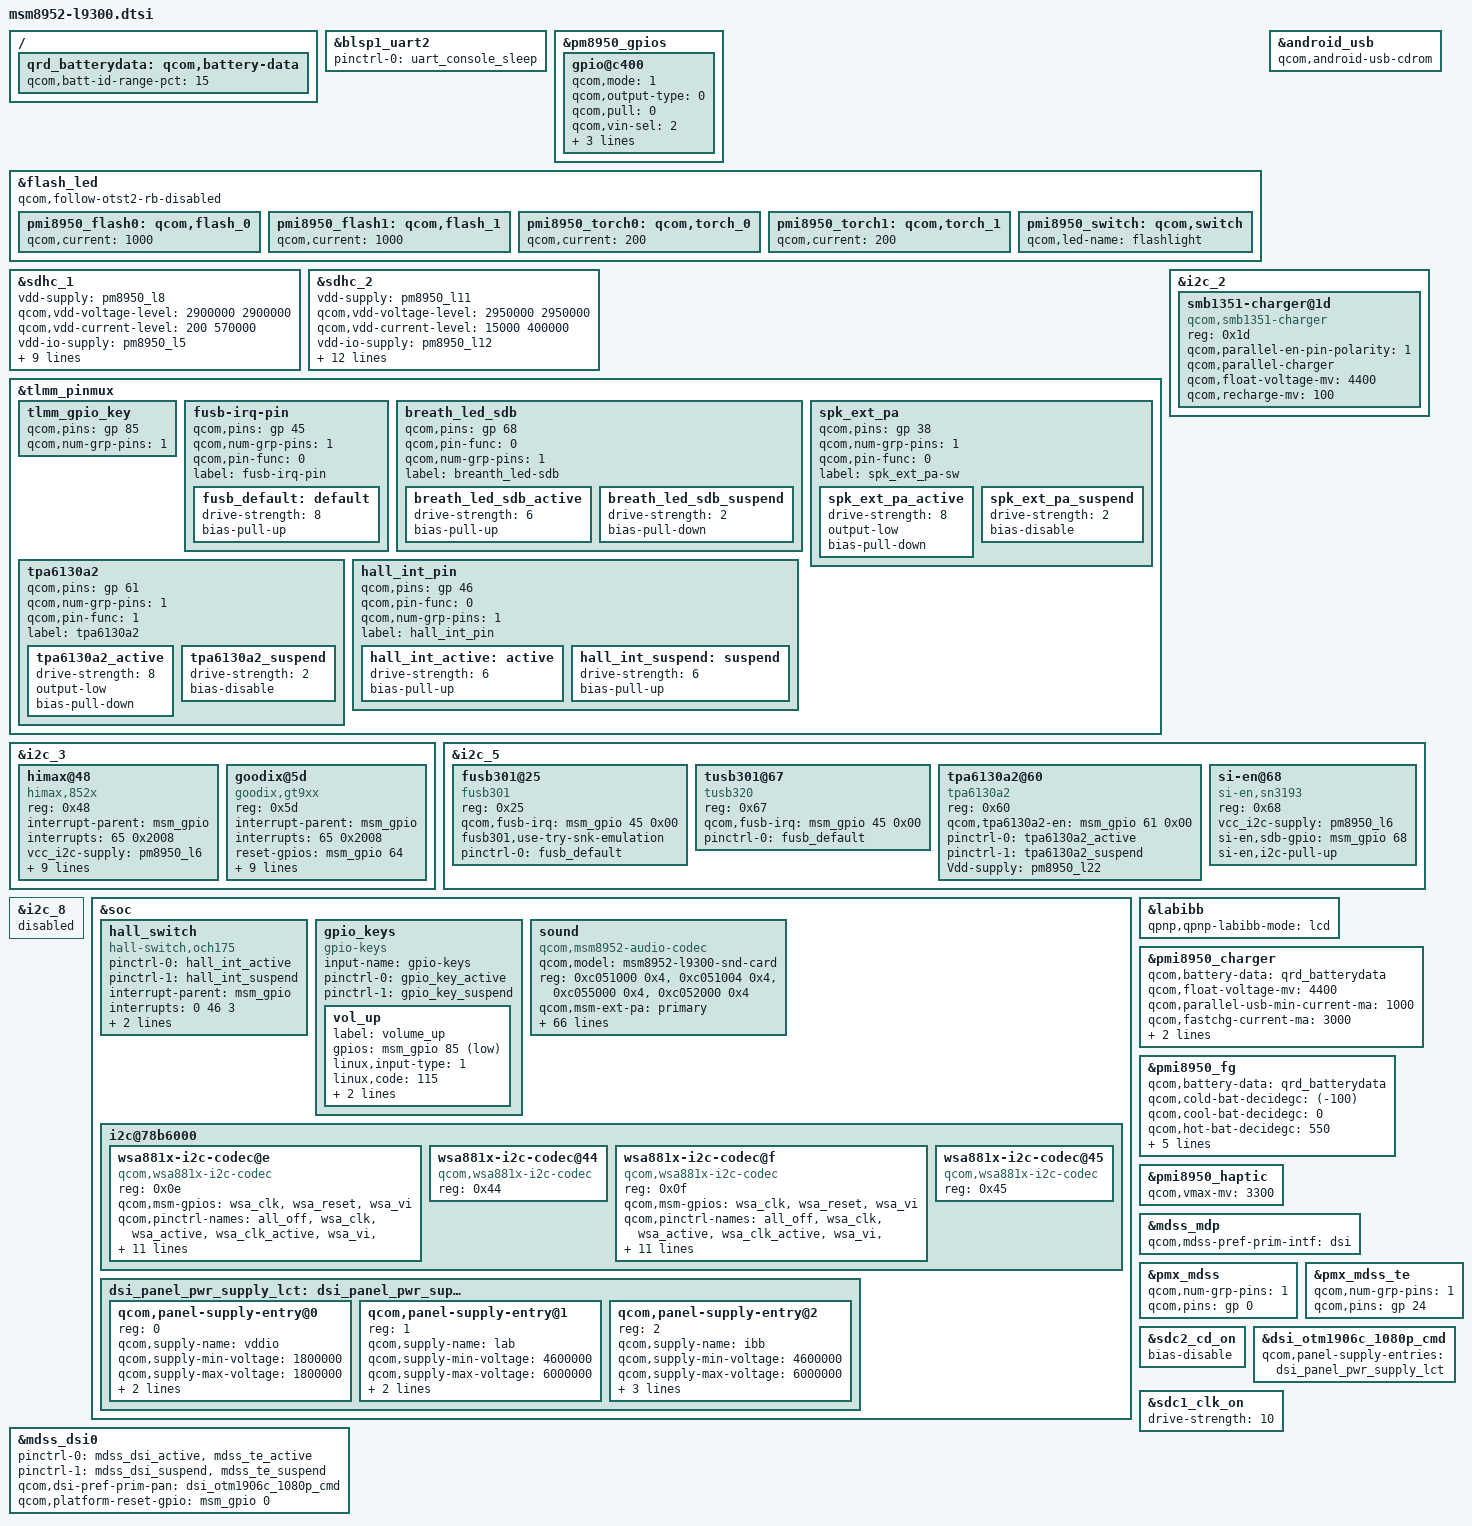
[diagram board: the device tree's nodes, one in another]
/*
 * Copyright (c) 2015, The Linux Foundation. All rights reserved.
 *
 * This program is free software; you can redistribute it and/or modify
 * it under the terms of the GNU General Public License version 2 and
 * only version 2 as published by the Free Software Foundation.
 *
 * This program is distributed in the hope that it will be useful,
 * but WITHOUT ANY WARRANTY; without even the implied warranty of
 * MERCHANTABILITY or FITNESS FOR A PARTICULAR PURPOSE.  See the
 * GNU General Public License for more details.
 */

#include "msm8952.dtsi"
#include "msm8952-camera-sensor-l9300.dtsi"
#include "dsi-panel-truly-hx8399c-1080p-video.dtsi"
#include "dsi-panel-dijing-otm1901a-1080p-video.dtsi"
#include "dsi-panel-truly-r63350-1080p-video.dtsi"

&blsp1_uart2 {
        status = "ok";
        pinctrl-names = "default";
        pinctrl-0 = <&uart_console_sleep>;
};

&pm8950_gpios {
        gpio@c400 {
                qcom,mode = <1>;
                qcom,output-type = <0>;
                qcom,pull = <0>;
                qcom,vin-sel = <2>;
                qcom,out-strength = <3>;
                qcom,src-sel = <0>;
                qcom,master-en = <1>;
                status = "okay";
        };
};

&flash_led {
        qcom,follow-otst2-rb-disabled;

        pmi8950_flash0: qcom,flash_0 {
                qcom,current = <1000>;
        };
        pmi8950_flash1: qcom,flash_1 {
                qcom,current = <1000>;
        };
        pmi8950_torch0: qcom,torch_0 {
                qcom,current = <200>;
        };
        pmi8950_torch1: qcom,torch_1 {
                qcom,current = <200>;
        };
        pmi8950_switch: qcom,switch {
                qcom,led-name = "flashlight";
        };
};

&sdhc_1 {
        vdd-supply = <&pm8950_l8>;
        qcom,vdd-voltage-level = <2900000 2900000>;
        qcom,vdd-current-level = <200 570000>;

        vdd-io-supply = <&pm8950_l5>;
        qcom,vdd-io-always-on;
        qcom,vdd-io-lpm-sup;
        qcom,vdd-io-voltage-level = <1800000 1800000>;
        qcom,vdd-io-current-level = <200 325000>;

        pinctrl-names = "active", "sleep";
        pinctrl-0 = <&sdc1_clk_on &sdc1_cmd_on &sdc1_data_on &sdc1_rclk_on>;
        pinctrl-1 = <&sdc1_clk_off &sdc1_cmd_off &sdc1_data_off &sdc1_rclk_off>;

        qcom,nonremovable;

        status = "ok";
};

&sdhc_2 {
        vdd-supply = <&pm8950_l11>;
        qcom,vdd-voltage-level = <2950000 2950000>;
        qcom,vdd-current-level = <15000 400000>;

        vdd-io-supply = <&pm8950_l12>;
        qcom,vdd-io-voltage-level = <1800000 2950000>;
        qcom,vdd-io-current-level = <200 22000>;

        pinctrl-names = "active", "sleep";
        pinctrl-0 = <&sdc2_clk_on &sdc2_cmd_on &sdc2_data_on &sdc2_cd_on>;
        pinctrl-1 = <&sdc2_clk_off &sdc2_cmd_off &sdc2_data_off &sdc2_cd_off>;

        #address-cells = <0>;
        interrupt-parent = <&sdhc_2>;
        interrupts = <0 1 2>;
        #interrupt-cells = <1>;
        interrupt-map-mask = <0xffffffff>;
        interrupt-map = <0 &intc 0 125 0
                        1 &intc 0 221 0
                        2 &msm_gpio 67 0>;
        interrupt-names = "hc_irq", "pwr_irq", "status_irq";
        cd-gpios = <&msm_gpio 67 0x0>;

        status = "ok";
};

&android_usb {
        qcom,android-usb-cdrom;
};

&tlmm_pinmux {
	tlmm_gpio_key {
		qcom,pins = <&gp 85>;
		qcom,num-grp-pins = <1>;
	};

	fusb-irq-pin {
		qcom,pins = <&gp 45>;
		qcom,num-grp-pins = <1>;
		qcom,pin-func = <0>;
		label = "fusb-irq-pin";
		fusb_default: default {
			drive-strength = <8>;
			bias-pull-up;
		};
	};

	breath_led_sdb {
		/* sn3193 breath led */
		qcom,pins = <&gp 68>;
		qcom,pin-func = <0>;
		qcom,num-grp-pins = <1>;
		label = "breanth_led-sdb";
		breath_led_sdb_active: breath_led_sdb_active {
			drive-strength = <6>;
			bias-pull-up;
		};
		breath_led_sdb_suspend: breath_led_sdb_suspend {
			drive-strength = <2>;
			bias-pull-down;
		};
	};

	spk_ext_pa {
		qcom,pins = <&gp 38>;
		qcom,num-grp-pins = <1>;
		qcom,pin-func = <0>;
		label = "spk_ext_pa-sw";
		spk_ext_pa_active: spk_ext_pa_active {
			drive-strength = <8>;
			output-low;
			bias-pull-down;
		};
		spk_ext_pa_suspend: spk_ext_pa_suspend {
			drive-strength = <2>;
			bias-disable;
		};
	};

	tpa6130a2 {
		qcom,pins = <&gp 61>;
		qcom,num-grp-pins = <1>;
		qcom,pin-func = <1>;
		label = "tpa6130a2";
		tpa6130a2_active: tpa6130a2_active {
			drive-strength = <8>;
			output-low;
			bias-pull-down;
		};
		tpa6130a2_suspend: tpa6130a2_suspend {
			drive-strength = <2>;
			bias-disable;
		};
	};

	hall_int_pin {
		qcom,pins = <&gp 46>;
		qcom,pin-func = <0>;
		qcom,num-grp-pins = <1>;
		label = "hall_int_pin";
		hall_int_active: active {
			drive-strength = <6>;
			bias-pull-up;
		};
		hall_int_suspend: suspend {
			drive-strength = <6>;
			bias-pull-up;
		};
	};
};

&i2c_2 {
	/* Parallel-charger configuration */
	smb1351-charger@1d {
		compatible = "qcom,smb1351-charger";
		reg = <0x1d>;
		qcom,parallel-en-pin-polarity = <1>;
		qcom,parallel-charger;
		qcom,float-voltage-mv = <4400>;
		qcom,recharge-mv = <100>;
	};
};

&i2c_3 { /* BLSP1 QUP3 */
	himax@48{
		compatible = "himax,852x";
		reg = <0x48>;
		interrupt-parent = <&msm_gpio>;
		interrupts = <65 0x2008>;
		vcc_i2c-supply = <&pm8950_l6>;
		himax,family-id = <0x82>;
		himax,reset-gpio = <&msm_gpio 64 0x0>;
		himax,power_ldo-gpio = <&msm_gpio 91 0x0>;
		himax,irq-gpio = <&msm_gpio 65 0x2008>;
		himax,display-coords = <0 1080 0 1920>;
		himax,panel-coords = <0 1080 0 1920>;
		himax,button-map = <139 102 158>;
		himax,i2c-pull-up;
		report_type = <1>;
	};

	goodix@5d {
		compatible = "goodix,gt9xx";
		reg = <0x5d>;
		interrupt-parent = <&msm_gpio>;
		interrupts = <65 0x2008>;
		reset-gpios = <&msm_gpio 64 0x00>;
		interrupt-gpios = <&msm_gpio 65 0x00>;
		power_ldo-gpios = <&msm_gpio 91 0x00>;
		goodix,panel-coords = <0 0 1080 1920>;
		goodix,display-coords = <0 0 1080 1920>;
		goodix,product-id = "970";
		goodix,fw_name = "goodix_firmware.bin";
		goodix,driver-send-cfg;
		goodix,cfg-data0 = [
			45 38 04 80 07 0A 35 04
			01 06 23 0B 55 3C 0A 05
			00 00 00 00 10 00 08 17
			19 1C 14 8C 2C 0E 3C 3E
			43 06 B5 06 01 43 33 11
			00 00 00 00 00 05 03 32
			00 00 2A 28 50 94 C0 02
			00 00 00 04 A5 2A 00 93
			31 00 86 38 00 79 41 00
			70 4A 00 70 00 00 00 00
			00 00 00 00 00 00 32 05
			01 00 00 00 00 00 FF 7F
			00 00 00 00 00 00 00 00
			00 14 46 00 00 00 00 32
			02 04 06 08 0A 0C 0E 10
			12 14 16 18 1A 1C 00 00
			00 00 00 00 00 00 00 00
			00 00 00 00 00 00 14 13
			12 10 0F 0C 0A 08 06 04
			02 00 16 18 1C 1D 1E 1F
			20 21 22 24 26 28 FF FF
			00 00 00 00 00 00 00 00
			00 00 00 00 00 00 00 00
			24 01
		];
	};
};

&i2c_5 {
	fusb301@25 {
		compatible = "fusb301";
		reg = <0x25>;
		qcom,fusb-irq = <&msm_gpio 45 0x00>;
		pinctrl-names = "default";
		fusb301,use-try-snk-emulation;
		pinctrl-0 = <&fusb_default>;
	};

	tusb301@67 {
		compatible = "tusb320";
		reg = <0x67>;
		qcom,fusb-irq = <&msm_gpio 45 0x00>;
		pinctrl-names = "default";
		pinctrl-0 = <&fusb_default>;
	};

	tpa6130a2@60 {
		compatible = "tpa6130a2";
		reg = <0x60>;
		qcom,tpa6130a2-en = <&msm_gpio 61 0x00>;
		pinctrl-names = "tpa6130a2_act",
					    "tpa6130a2_sus";
		pinctrl-0 = <&tpa6130a2_active>;
		pinctrl-1 = <&tpa6130a2_suspend>;
		Vdd-supply=<&pm8950_l22>;
	};
	si-en@68{ /* breanth led */
		compatible = "si-en,sn3193";
		reg = <0x68>;
		vcc_i2c-supply = <&pm8950_l6>;
		si-en,sdb-gpio = <&msm_gpio 68 0>;
		si-en,i2c-pull-up;
	};
};

&i2c_8 {
	status = "disabled";
};

&soc {
	hall_switch {
		compatible = "hall-switch,och175";
		pinctrl-names = "hall_active","hall_suspend";
		pinctrl-0 = <&hall_int_active>;
		pinctrl-1 = <&hall_int_suspend>;
		interrupt-parent = <&msm_gpio>;
		interrupts = <0 46 3>;
		vdd-supply = <&pm8950_l6>;
		interrupt-names = "hall-irq";
		hall,irq-gpio = <&msm_gpio 46 0x00>;
	};

	gpio_keys {
		compatible = "gpio-keys";
		input-name = "gpio-keys";
		pinctrl-names = "tlmm_gpio_key_active","tlmm_gpio_key_suspend";
		pinctrl-0 = <&gpio_key_active>;
		pinctrl-1 = <&gpio_key_suspend>;

		vol_up {
			label = "volume_up";
			gpios = <&msm_gpio 85 0x1>;
			linux,input-type = <1>;
			linux,code = <115>;
			gpio-key,wakeup;
			debounce-interval = <15>;
		};

	};

	sound {
		compatible = "qcom,msm8952-audio-codec";
		qcom,model = "msm8952-l9300-snd-card";
		reg = <0xc051000 0x4>,
		      <0xc051004 0x4>,
		      <0xc055000 0x4>,
		      <0xc052000 0x4>;
		reg-names = "csr_gp_io_mux_mic_ctl",
			    "csr_gp_io_mux_spkr_ctl",
			    "csr_gp_io_lpaif_pri_pcm_pri_mode_muxsel",
			    "csr_gp_io_mux_quin_ctl";

		qcom,msm-ext-pa = "primary";
		qcom,msm-mclk-freq = <9600000>;
		qcom,msm-mbhc-hphl-swh = <1>;
		qcom,msm-mbhc-gnd-swh = <0>;
		qcom,msm-hs-micbias-type = "internal";
		qcom,msm-micbias1-ext-cap;
		qcom,msm-micbias2-ext-cap;
		qcom,spk_ext_pa = <&msm_gpio 38 0x0>;
		qcom,audio-routing =
			"RX_BIAS", "MCLK",
			"SPK_RX_BIAS", "MCLK",
			"INT_LDO_H", "MCLK",
			"MIC BIAS External", "Handset Mic",
			"MIC BIAS Internal2", "Headset Mic",
			"MIC BIAS External", "Secondary Mic",
			"AMIC1", "MIC BIAS External",
			"AMIC2", "MIC BIAS Internal2",
			"AMIC3", "MIC BIAS External",
			"WSA_SPK OUT", "VDD_WSA_SWITCH",
			"SpkrMono WSA_IN", "WSA_SPK OUT";
		qcom,msm-gpios =
			"pri_i2s", // ;
			"spk_ext_pa-sw";
		qcom,pinctrl-names =
			"all_off",
			"pri_i2s_act", // ;
			"spk_ext_pa_act",
			"spk_ext_pa_sus";
		pinctrl-names =
			"all_off",
			"pri_i2s_act", // ;
			"spk_ext_pa_act",
			"spk_ext_pa_sus";
		pinctrl-0 = <&cdc_pdm_lines_sus &cdc_pdm_lines_2_sus>;
		pinctrl-1 = <&cdc_pdm_lines_act &cdc_pdm_lines_2_act>;
		pinctrl-2 = <&spk_ext_pa_active>;
		pinctrl-3 = <&spk_ext_pa_suspend>;
		asoc-platform = <&pcm0>, <&pcm1>, <&pcm2>, <&voip>, <&voice>,
				<&loopback>, <&compress>, <&hostless>,
				<&afe>, <&lsm>, <&routing>, <&lpa>,
				<&voice_svc>;
		asoc-platform-names = "msm-pcm-dsp.0", "msm-pcm-dsp.1", "msm-pcm-dsp.2",
				"msm-voip-dsp", "msm-pcm-voice", "msm-pcm-loopback",
				"msm-compress-dsp", "msm-pcm-hostless", "msm-pcm-afe",
				"msm-lsm-client", "msm-pcm-routing", "msm-pcm-lpa",
				"msm-voice-svc";
		asoc-cpu = <&dai_pri_auxpcm>, <&dai_hdmi>,
				<&dai_mi2s0>, <&dai_mi2s1>, <&dai_mi2s2>, <&dai_mi2s3>,
				<&dai_mi2s5>, <&dai_mi2s6>,
				<&sb_0_rx>, <&sb_0_tx>, <&sb_1_rx>, <&sb_1_tx>,
				<&sb_3_rx>, <&sb_3_tx>, <&sb_4_rx>, <&sb_4_tx>,
				<&bt_sco_rx>, <&bt_sco_tx>, <&int_fm_rx>, <&int_fm_tx>,
				<&afe_pcm_rx>, <&afe_pcm_tx>, <&afe_proxy_rx>, <&afe_proxy_tx>,
				<&incall_record_rx>, <&incall_record_tx>, <&incall_music_rx>,
				<&incall_music_2_rx>;
		asoc-cpu-names = "msm-dai-q6-auxpcm.1", "msm-dai-q6-hdmi.8",
				"msm-dai-q6-mi2s.0", "msm-dai-q6-mi2s.1",
				"msm-dai-q6-mi2s.2", "msm-dai-q6-mi2s.3",
				"msm-dai-q6-mi2s.5", "msm-dai-q6-mi2s.6",
				"msm-dai-q6-dev.16384", "msm-dai-q6-dev.16385",
				"msm-dai-q6-dev.16386", "msm-dai-q6-dev.16387",
				"msm-dai-q6-dev.16390", "msm-dai-q6-dev.16391",
				"msm-dai-q6-dev.16392", "msm-dai-q6-dev.16393",
				"msm-dai-q6-dev.12288", "msm-dai-q6-dev.12289",
				"msm-dai-q6-dev.12292", "msm-dai-q6-dev.12293",
				"msm-dai-q6-dev.224", "msm-dai-q6-dev.225",
				"msm-dai-q6-dev.241", "msm-dai-q6-dev.240",
				"msm-dai-q6-dev.32771", "msm-dai-q6-dev.32772",
				"msm-dai-q6-dev.32773", "msm-dai-q6-dev.32770";
		asoc-codec = <&stub_codec>, <&pm8950_cajon_dig>;
		asoc-codec-names = "msm-stub-codec.1", "cajon_codec";
		asoc-wsa-codec-names = "wsa881x-i2c-codec.2-000f";
		asoc-wsa-codec-prefixes = "SpkrMono";

		msm-vdd-wsa-switch-supply = <&pm8950_l13>;
		qcom,msm-vdd-wsa-switch-voltage = <3075000>;
		qcom,msm-vdd-wsa-switch-current = <5000>;
	};

	i2c@78b6000 {
		wsa881x-i2c-codec@e {
			compatible = "qcom,wsa881x-i2c-codec";
			reg = <0x0e>;
			qcom,msm-gpios = "wsa_clk",
					"wsa_reset",
					"wsa_vi";
			qcom,pinctrl-names = "all_off",
					"wsa_clk",
					"wsa_active",
					"wsa_clk_active",
					"wsa_vi",
					"wsa_clk_vi",
					"wsa_active_vi",
					"wsa_all";
			pinctrl-names = "all_off",
					"wsa_clk",
					"wsa_active",
					"wsa_clk_active",
					"wsa_vi",
					"wsa_clk_vi",
					"wsa_active_vi",
					"wsa_all";
			pinctrl-0 = <&wsa_clk_off &wsa_suspend &wsa_vi_sus>;
			pinctrl-1 = <&wsa_clk_on &wsa_suspend &wsa_vi_sus>;
			pinctrl-2 = <&wsa_clk_off &wsa_active &wsa_vi_sus>;
			pinctrl-3 = <&wsa_clk_on &wsa_active &wsa_vi_sus>;
			pinctrl-4 = <&wsa_clk_off &wsa_suspend &wsa_vi_act>;
			pinctrl-5 = <&wsa_clk_on &wsa_suspend &wsa_vi_act>;
			pinctrl-6 = <&wsa_clk_off &wsa_active &wsa_vi_act>;
			pinctrl-7 = <&wsa_clk_on &wsa_active &wsa_vi_act>;
		};
		wsa881x-i2c-codec@44 {
			compatible = "qcom,wsa881x-i2c-codec";
			reg = <0x44>;
		};
		wsa881x-i2c-codec@f {
			compatible = "qcom,wsa881x-i2c-codec";
			reg = <0x0f>;
			qcom,msm-gpios = "wsa_clk",
					"wsa_reset",
					"wsa_vi";
			qcom,pinctrl-names = "all_off",
					"wsa_clk",
					"wsa_active",
					"wsa_clk_active",
					"wsa_vi",
					"wsa_clk_vi",
					"wsa_active_vi",
					"wsa_all";
			pinctrl-names = "all_off",
					"wsa_clk",
					"wsa_active",
					"wsa_clk_active",
					"wsa_vi",
					"wsa_clk_vi",
					"wsa_active_vi",
					"wsa_all";
			pinctrl-0 = <&wsa_clk_off &wsa_suspend &wsa_vi_sus>;
			pinctrl-1 = <&wsa_clk_on &wsa_suspend &wsa_vi_sus>;
			pinctrl-2 = <&wsa_clk_off &wsa_active &wsa_vi_sus>;
			pinctrl-3 = <&wsa_clk_on &wsa_active &wsa_vi_sus>;
			pinctrl-4 = <&wsa_clk_off &wsa_suspend &wsa_vi_act>;
			pinctrl-5 = <&wsa_clk_on &wsa_suspend &wsa_vi_act>;
			pinctrl-6 = <&wsa_clk_off &wsa_active &wsa_vi_act>;
			pinctrl-7 = <&wsa_clk_on &wsa_active &wsa_vi_act>;
		};
		wsa881x-i2c-codec@45 {
			compatible = "qcom,wsa881x-i2c-codec";
			reg = <0x45>;
		};
	};

	dsi_panel_pwr_supply_lct: dsi_panel_pwr_supply {
		#address-cells = <1>;
		#size-cells = <0>;

		qcom,panel-supply-entry@0 {
			reg = <0>;
			qcom,supply-name = "vddio";
			qcom,supply-min-voltage = <1800000>;
			qcom,supply-max-voltage = <1800000>;
			qcom,supply-enable-load = <100000>;
			qcom,supply-disable-load = <100>;
		};

		qcom,panel-supply-entry@1 {
			reg = <1>;
			qcom,supply-name = "lab";
			qcom,supply-min-voltage = <4600000>;
			qcom,supply-max-voltage = <6000000>;
			qcom,supply-enable-load = <100000>;
			qcom,supply-disable-load = <100>;
		};

		qcom,panel-supply-entry@2 {
			reg = <2>;
			qcom,supply-name = "ibb";
			qcom,supply-min-voltage = <4600000>;
			qcom,supply-max-voltage = <6000000>;
			qcom,supply-enable-load = <100000>;
			qcom,supply-disable-load = <100>;
			qcom,supply-post-on-sleep = <20>;
		};
	};
};

&labibb {
	status = "ok";
	qpnp,qpnp-labibb-mode = "lcd";
};

/ {
	qrd_batterydata: qcom,battery-data {
		qcom,batt-id-range-pct = <15>;
		#include "batterydata-4v4-3100mah-l9300.dtsi"
	};
};

&pmi8950_charger {
	qcom,battery-data = <&qrd_batterydata>;
	qcom,float-voltage-mv = <4400>;
	/delete-property/ qcom,chg-led-sw-controls;
	/delete-property/ qcom,chg-led-support;
	qcom,parallel-usb-min-current-ma = <1000>;
	qcom,fastchg-current-ma = <3000>;
	qcom,fastchg-current-comp = <700>;
	qcom,thermal-mitigation = <2000 1800 1000 0>;
	status = "okay";
};

&pmi8950_fg {
	qcom,battery-data = <&qrd_batterydata>;
	qcom,cold-bat-decidegc = <(-100)>;
	qcom,cool-bat-decidegc = <0>;
	qcom,hot-bat-decidegc = <550>;
	qcom,warm-bat-decidegc = <450>;
	qcom,ext-sense-type;
	qcom,fg-delta-soc = <1>;
	qcom,resume-soc = <99>;
	qcom,resume-soc-raw = <254>;
};

&pmi8950_haptic {
	qcom,vmax-mv = <3300>;
};

&mdss_mdp {
	qcom,mdss-pref-prim-intf = "dsi";
};

&pmx_mdss {
	qcom,num-grp-pins = <1>;
	qcom,pins = <&gp 0>;
};

&pmx_mdss_te {
	qcom,num-grp-pins = <1>;
	qcom,pins = <&gp 24>;
};

&mdss_dsi0 {
	pinctrl-names = "mdss_default", "mdss_sleep";
	pinctrl-0 = <&mdss_dsi_active &mdss_te_active>;
	pinctrl-1 = <&mdss_dsi_suspend &mdss_te_suspend>;
	qcom,dsi-pref-prim-pan = <&dsi_otm1906c_1080p_cmd>;

	qcom,platform-reset-gpio = <&msm_gpio 0 0>;
	/delete-property/ vdd-supply;
};

&sdc2_cd_on {
	/delete-property/ bias-pull-up;
	bias-disable;
};

&dsi_otm1906c_1080p_cmd {
	qcom,panel-supply-entries = <&dsi_panel_pwr_supply_lct>;
};

&sdc1_clk_on {
	drive-strength = <10>; /* 10 MA */
};
